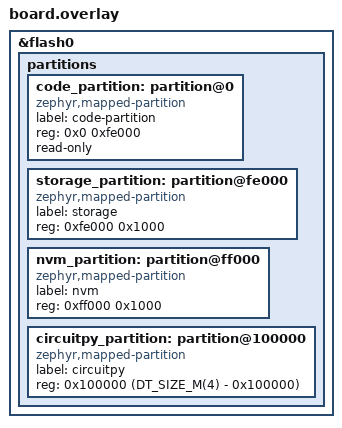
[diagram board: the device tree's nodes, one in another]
&flash0 {
	partitions {
		#address-cells = <1>;
		#size-cells = <1>;

		code_partition: partition@0 {
			compatible = "zephyr,mapped-partition";
			label = "code-partition";
			reg = <0x0 0xfe000>;
			read-only;
		};

		storage_partition: partition@fe000 {
			compatible = "zephyr,mapped-partition";
			label = "storage";
			reg = <0xfe000 0x1000>;
		};

		nvm_partition: partition@ff000 {
			compatible = "zephyr,mapped-partition";
			label = "nvm";
			reg = <0xff000 0x1000>;
		};

		circuitpy_partition: partition@100000 {
			compatible = "zephyr,mapped-partition";
			label = "circuitpy";
			reg = <0x100000 (DT_SIZE_M(4) - 0x100000)>;
		};
	};
};

#include "../../../app.overlay"
